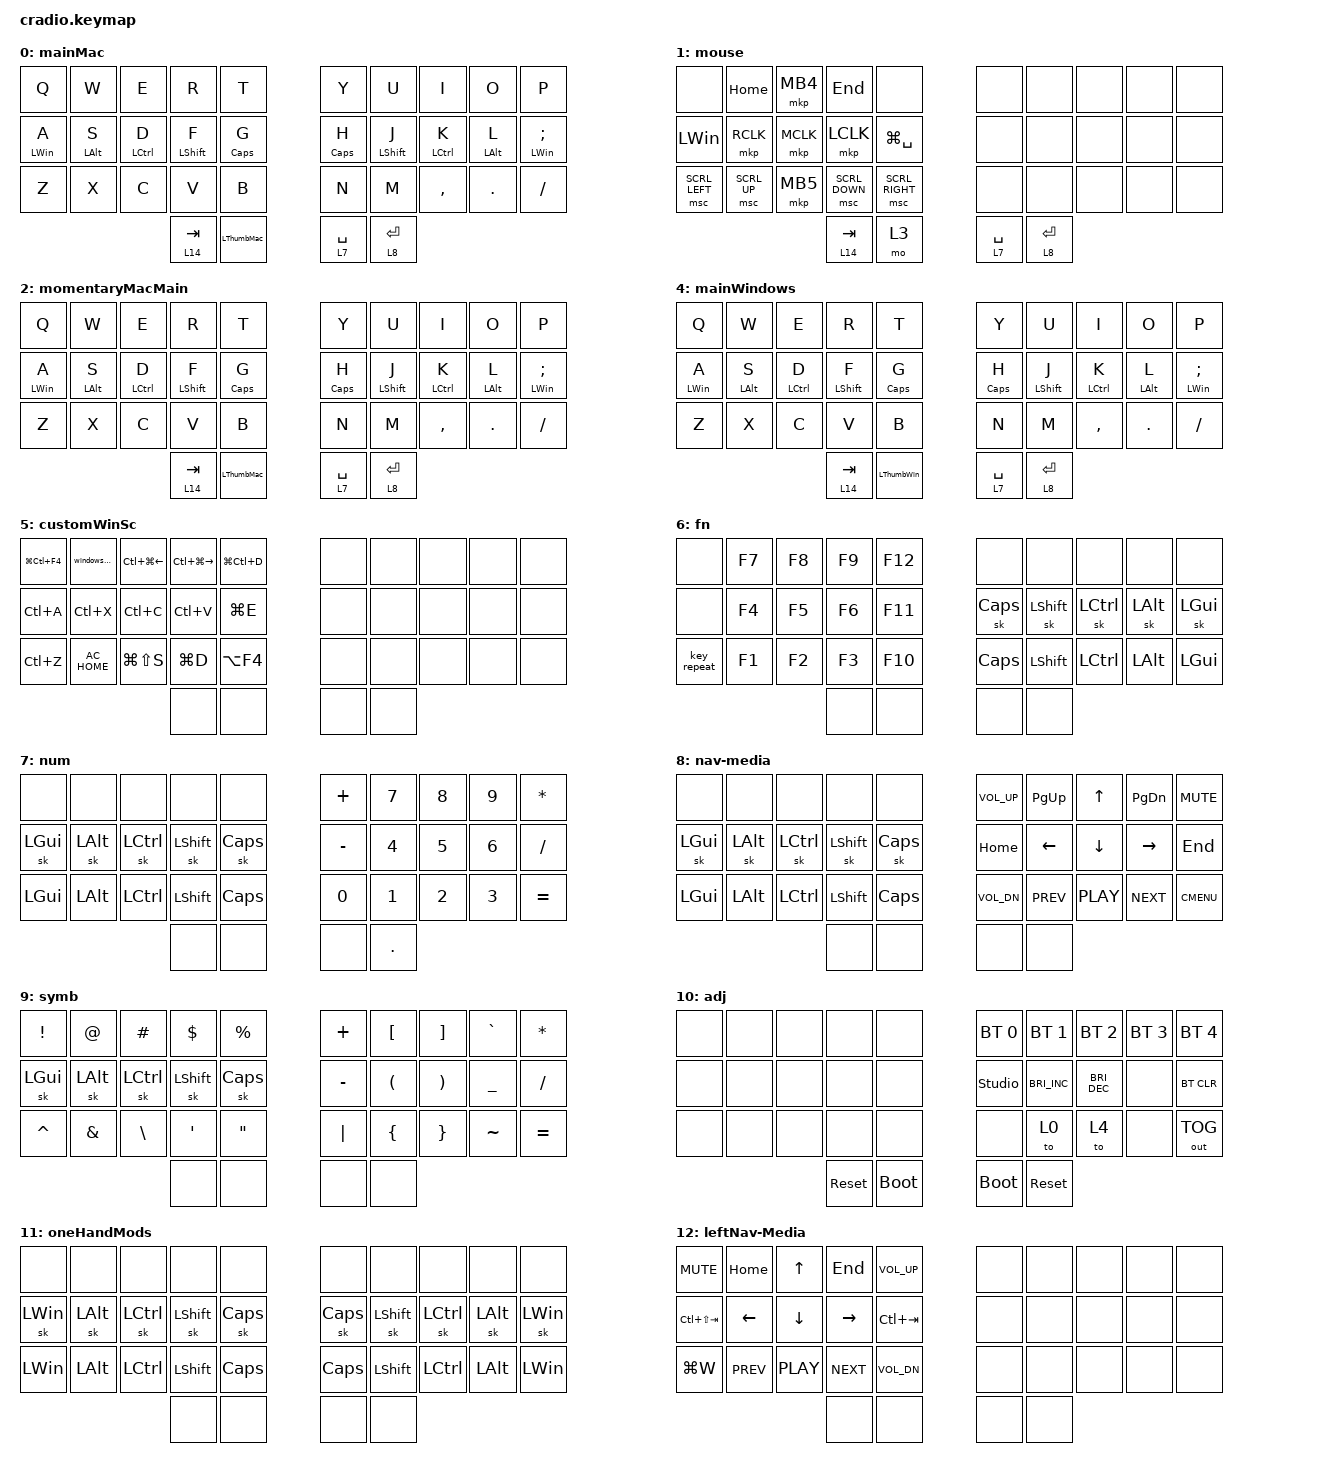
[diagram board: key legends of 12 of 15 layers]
#define ZMK_POINTING_DEFAULT_MOVE_VAL 1500  // default: 600
#define ZMK_POINTING_DEFAULT_SCRL_VAL 20    // default: 10

#include <behaviors.dtsi>
#include <dt-bindings/zmk/bt.h>
#include <dt-bindings/zmk/keys.h>
#include <dt-bindings/zmk/outputs.h>
#include <dt-bindings/zmk/pointing.h>

&sk {
    quick-release;
    lazy;
    release-after-ms = <800>;
};

&lt {
    flavor = "balanced";
    require-prior-idle-ms = <40>;
};

/ {
    behaviors {
        hmr: hmr {
            compatible = "zmk,behavior-hold-tap";
            #binding-cells = <2>;
            label = "hmr";
            bindings = <&kp>, <&kp>;

            tapping-term-ms = <280>;
            hold-trigger-on-release;             // delay positional check until key-release
            flavor = "balanced";
            require-prior-idle-ms = <200>;
            require-prior-idle-ms = <150>;
            quick-tap-ms = <175>;
            hold-trigger-key-positions = <0 1 2 3 4 10 11 12 13 14 20 21 22 23 24 30 31 32 33>;
        };

        hml: hml {
            compatible = "zmk,behavior-hold-tap";
            #binding-cells = <2>;
            label = "hml";
            bindings = <&kp>, <&kp>;

            tapping-term-ms = <280>;
            hold-trigger-on-release;
            flavor = "balanced";
            require-prior-idle-ms = <200>;
            quick-tap-ms = <175>;
            hold-trigger-key-positions = <5 6 7 8 9 15 16 17 18 19 25 26 27 28 29 32 33 30 31>;
        };

        tapSk_holdLayer: tapSk_holdLayer {
            compatible = "zmk,behavior-hold-tap";
            label = "TAPSK_HOLDLAYER";
            bindings = <&mo>, <&sk>;

            #binding-cells = <2>;
            tapping-term-ms = <80>;
            flavor = "tap-preferred";
            hold-while-undecided;
        };

        LThumbMac: LThumbMac {
            compatible = "zmk,behavior-tap-dance";
            label = "LTHUMBMAC";
            #binding-cells = <0>;
            bindings = <&tapSk_holdLayer 3 LEFT_SHIFT>, <&lt 5 LG(SPACE)>;

            tapping-term-ms = <380>;
        };

        tapToHoldMo: tapToHoldMo {
            compatible = "zmk,behavior-hold-tap";
            label = "TAPTOHOLDMO";
            #binding-cells = <2>;
            tapping-term-ms = <150>;
            flavor = "tap-preferred";
            hold-while-undecided;
            bindings = <&mo>, <&to>;
        };

        LThumbWin: LThumbWin {
            compatible = "zmk,behavior-tap-dance";
            label = "LTHUMBWIN";
            #binding-cells = <0>;
            bindings = <&tapSk_holdLayer 5 LEFT_SHIFT>, <&lt 0 LEFT_WIN>;

            tapping-term-ms = <380>;
        };
    };

    combos {
        compatible = "zmk,combos";

        capWords {
            bindings = <&caps_word>;
            key-positions = <13 16>;
            timeout-ms = <150>;
            require-prior-idle-ms = <100>;
        };

        toSymb {
            bindings = <&mo 9>;
            key-positions = <31 32>;
            timeout-ms = <150>;
            require-prior-idle-ms = <100>;
            slow-release;
        };

        escL {
            timeout-ms = <40>;
            bindings = <&kp ESCAPE>;
            key-positions = <3 2>;
            require-prior-idle-ms = <100>;
        };

        aphostrope {
            timeout-ms = <35>;
            bindings = <&kp SQT>;
            key-positions = <8 7>;
        };

        backR {
            bindings = <&kp BACKSPACE>;
            key-positions = <16 17>;
            timeout-ms = <40>;
            require-prior-idle-ms = <100>;
        };

        backL {
            bindings = <&kp BACKSPACE>;
            key-positions = <12 13>;
            timeout-ms = <40>;
            require-prior-idle-ms = <100>;
        };

        questionR {
            bindings = <&kp QUESTION>;
            key-positions = <27 28>;
            timeout-ms = <70>;
            require-prior-idle-ms = <40>;
        };

        wordDelLMac {
            bindings = <&kp LA(BACKSPACE)>;
            key-positions = <12 11>;
            timeout-ms = <40>;
            require-prior-idle-ms = <100>;
            layers = <0>;
        };

        wordDelRMac {
            bindings = <&kp LA(BACKSPACE)>;
            key-positions = <17 18>;
            timeout-ms = <40>;
            require-prior-idle-ms = <100>;
            layers = <0>;
        };

        delR {
            bindings = <&kp DELETE>;
            key-positions = <26 27>;
            timeout-ms = <40>;
            require-prior-idle-ms = <100>;
        };

        delL {
            bindings = <&kp DELETE>;
            key-positions = <22 23>;
            timeout-ms = <40>;
            require-prior-idle-ms = <100>;
        };

        LhandOHM {
            bindings = <&mo 11>;
            key-positions = <30 13>;
            timeout-ms = <40>;
            slow-release;
            require-prior-idle-ms = <100>;
        };

        RhandOHM {
            bindings = <&mo 11>;
            key-positions = <33 16>;
            timeout-ms = <40>;
            slow-release;
            require-prior-idle-ms = <100>;
        };

        toAdj {
            bindings = <&mo 10>;
            key-positions = <0 4>;
            timeout-ms = <150>;
            slow-release;
            require-prior-idle-ms = <100>;
        };

        toLeftMedia-Nav {
            bindings = <&mo 12>;
            key-positions = <31 1 2 3>;
            timeout-ms = <150>;
            slow-release;
            require-prior-idle-ms = <100>;
        };

        rightToLeft {
            bindings = <&sl 13>;
            key-positions = <12 11 13>;
            timeout-ms = <200>;
            slow-release;
            require-prior-idle-ms = <100>;
        };

        appWindows {
            bindings = <&kp LC(LA(DOWN))>;
            key-positions = <10 30>;
            timeout-ms = <40>;
            require-prior-idle-ms = <100>;
        };

        leftEnter {
            bindings = <&kp ENTER>;
            key-positions = <21 22>;
            timeout-ms = <40>;
            slow-release;
            require-prior-idle-ms = <80>;
        };

        wordDelRWin {
            bindings = <&kp LC(BACKSPACE)>;
            key-positions = <17 18>;
            timeout-ms = <40>;
            require-prior-idle-ms = <100>;
            layers = <4>;
        };

        wordDelLWin {
            bindings = <&kp LC(BACKSPACE)>;
            key-positions = <12 11>;
            timeout-ms = <40>;
            require-prior-idle-ms = <100>;
            layers = <4>;
        };

        toFn {
            bindings = <&mo 6>;
            key-positions = <11 12 13 31>;
            slow-release;
            timeout-ms = <40>;
            require-prior-idle-ms = <100>;
        };

        leftQuestion {
            bindings = <&kp QUESTION>;
            key-positions = <1 2>;
            timeout-ms = <70>;
            require-prior-idle-ms = <40>;
        };

        moMouse {
            bindings = <&mo 1>;
            key-positions = <31 13>;
            timeout-ms = <40>;
            slow-release;
            require-prior-idle-ms = <100>;
            layers = <0>;
        };

        openRecentlyClosed {
            bindings = <&kp LG(LS(T))>;
            key-positions = <1 0>;
            timeout-ms = <70>;
            require-prior-idle-ms = <40>;
        };

        newTab {
            bindings = <&kp LG(T)>;
            key-positions = <1 3>;
            timeout-ms = <70>;
            require-prior-idle-ms = <40>;
        };

        toMain {
            bindings = <&to 0>;
            key-positions = <13 20 31>;
            timeout-ms = <150>;
            slow-release;
            require-prior-idle-ms = <100>;
        };

        moMain {
            bindings = <&mo 2>;
            key-positions = <31 10 11 12 13>;
            timeout-ms = <150>;
            slow-release;
            require-prior-idle-ms = <100>;
        };

        toMouse {
            bindings = <&to 1>;
            key-positions = <31 10 13>;
            timeout-ms = <150>;
            slow-release;
            require-prior-idle-ms = <100>;
        };
    };

    macros {
        windowsMissionControl: new_macro {
            compatible = "zmk,behavior-macro";
            #binding-cells = <0>;
            bindings =
                <&macro_press>,
                <&kp LEFT_WIN>,
                <&macro_tap>,
                <&kp TAB>,
                <&macro_release>,
                <&kp LEFT_WIN>;

            label = "NEW_MACRO";
        };
    };

    keymap {
        compatible = "zmk,keymap";

        mainMac {
            bindings = <
&kp Q            &kp W            &kp E                &kp R              &kp T          &kp Y        &kp U              &kp I                &kp O            &kp P
&hml LEFT_WIN A  &hml LEFT_ALT S  &hml LEFT_CONTROL D  &hml LEFT_SHIFT F  &hml CAPS G    &hmr CAPS H  &hmr LEFT_SHIFT J  &hmr LEFT_CONTROL K  &hmr LEFT_ALT L  &hmr LEFT_WIN SEMICOLON
&kp Z            &kp X            &kp C                &kp V              &kp B          &kp N        &kp M              &kp COMMA            &kp DOT          &kp FSLH
                                                       &lt 14 TAB         &LThumbMac     &lt 7 SPACE  &lt 8 ENTER
            >;
        };

        mouse {
            bindings = <
&none           &kp HOME      &mkp MB4   &kp END         &none              &none        &none        &none  &none  &none
&kp LEFT_WIN    &mkp RCLK     &mkp MCLK  &mkp LCLK       &kp LG(SPACE)      &none        &none        &none  &none  &none
&msc SCRL_LEFT  &msc SCRL_UP  &mkp MB5   &msc SCRL_DOWN  &msc SCRL_RIGHT    &none        &none        &none  &none  &none
                                         &lt 14 TAB      &mo 3              &lt 7 SPACE  &lt 8 ENTER
            >;
        };

        momentaryMacMain {
            bindings = <
&kp Q            &kp W            &kp E                &kp R              &kp T          &kp Y        &kp U              &kp I                &kp O            &kp P
&hml LEFT_WIN A  &hml LEFT_ALT S  &hml LEFT_CONTROL D  &hml LEFT_SHIFT F  &hml CAPS G    &hmr CAPS H  &hmr LEFT_SHIFT J  &hmr LEFT_CONTROL K  &hmr LEFT_ALT L  &hmr LEFT_WIN SEMICOLON
&kp Z            &kp X            &kp C                &kp V              &kp B          &kp N        &kp M              &kp COMMA            &kp DOT          &kp FSLH
                                                       &lt 14 TAB         &LThumbMac     &lt 7 SPACE  &lt 8 ENTER
            >;
        };

        macShorcuts0 {
            bindings = <
&kp LS(LA(LC(LG(LEFT))))  &kp LG(LS(LC(LA(RIGHT))))  &kp LC(LG(LA(A)))         &kp LC(LG(LA(B)))     &kp LG(LC(D))    &none  &none  &none  &none  &none
&kp LG(A)                 &kp LG(X)                  &kp LG(C)                 &kp LG(V)             &kp LG(LC(F))    &none  &none  &none  &none  &none
&kp LG(Z)                 &kp LG(LS(N5))             &kp LG(LS(LC(NUMBER_4)))  &kp LG(D)             &kp LG(W)        &none  &none  &none  &none  &none
                                                                               &kp LG(LEFT_BRACKET)  &none            &none  &none
            >;
        };

        mainWindows {
            bindings = <
&kp Q            &kp W            &kp E                &kp R              &kp T          &kp Y        &kp U              &kp I                &kp O            &kp P
&hml LEFT_WIN A  &hml LEFT_ALT S  &hml LEFT_CONTROL D  &hml LEFT_SHIFT F  &hml CAPS G    &hmr CAPS H  &hmr LEFT_SHIFT J  &hmr LEFT_CONTROL K  &hmr LEFT_ALT L  &hmr LEFT_WIN SEMICOLON
&kp Z            &kp X            &kp C                &kp V              &kp B          &kp N        &kp M              &kp COMMA            &kp DOT          &kp FSLH
                                                       &lt 14 TAB         &LThumbWin     &lt 7 SPACE  &lt 8 ENTER
            >;
        };

        customWinSc {
            bindings = <
&kp LG(LC(F4))  &windowsMissionControl  &kp LC(LG(LEFT))  &kp LC(LG(RIGHT))  &kp LG(LC(D))    &none  &none  &none  &none  &none
&kp LC(A)       &kp LC(X)               &kp LC(C)         &kp LC(V)          &kp LG(E)        &none  &none  &none  &none  &none
&kp LC(Z)       &kp C_AC_HOME           &kp LG(LS(S))     &kp LG(D)          &kp LA(F4)       &none  &none  &none  &none  &none
                                                          &none              &none            &none  &none
            >;
        };

        fn {
            bindings = <
&none        &kp F7  &kp F8  &kp F9  &kp F12    &none     &none           &none      &none     &none
&none        &kp F4  &kp F5  &kp F6  &kp F11    &sk CAPS  &sk LEFT_SHIFT  &sk LCTRL  &sk LALT  &sk LEFT_GUI
&key_repeat  &kp F1  &kp F2  &kp F3  &kp F10    &kp CAPS  &kp LEFT_SHIFT  &kp LCTRL  &kp LALT  &kp LEFT_GUI
                             &none   &none      &none     &none
            >;
        };

        num {
            bindings = <
&none         &none     &none      &none           &none       &kp PLUS   &kp N7   &kp N8  &kp N9  &kp ASTERISK
&sk LEFT_GUI  &sk LALT  &sk LCTRL  &sk LSHFT       &sk CAPS    &kp MINUS  &kp N4   &kp N5  &kp N6  &kp SLASH
&kp LEFT_GUI  &kp LALT  &kp LCTRL  &kp LEFT_SHIFT  &kp CAPS    &kp N0     &kp N1   &kp N2  &kp N3  &kp EQUAL
                                   &none           &none       &none      &kp DOT
            >;
        };

        nav-media {
            bindings = <
&none         &none     &none      &none           &none       &kp C_VOL_UP  &kp PG_UP   &kp UP      &kp PG_DN   &kp C_MUTE
&sk LEFT_GUI  &sk LALT  &sk LCTRL  &sk LSHFT       &sk CAPS    &kp HOME      &kp LEFT    &kp DOWN    &kp RIGHT   &kp END
&kp LEFT_GUI  &kp LALT  &kp LCTRL  &kp LEFT_SHIFT  &kp CAPS    &kp C_VOL_DN  &kp C_PREV  &kp C_PLAY  &kp C_NEXT  &kp K_CMENU
                                   &none           &none       &none         &none
            >;
        };

        symb {
            bindings = <
&kp EXCL      &kp AT    &kp HASH       &kp DLLR          &kp PERCENT          &kp PLUS   &kp LEFT_BRACKET      &kp RIGHT_BRACKET      &kp GRAVE  &kp STAR
&sk LEFT_GUI  &sk LALT  &sk LCTRL      &sk LEFT_SHIFT    &sk CAPS             &kp MINUS  &kp LEFT_PARENTHESIS  &kp RIGHT_PARENTHESIS  &kp UNDER  &kp SLASH
&kp CARET     &kp AMPS  &kp BACKSLASH  &kp SINGLE_QUOTE  &kp DOUBLE_QUOTES    &kp PIPE   &kp LEFT_BRACE        &kp RIGHT_BRACE        &kp TILDE  &kp EQUAL
                                       &none             &none                &none      &none
            >;
        };

        adj {
            bindings = <
&none  &none  &none  &none       &none          &bt BT_SEL 0    &bt BT_SEL 1   &bt BT_SEL 2          &bt BT_SEL 3  &bt BT_SEL 4
&none  &none  &none  &none       &none          &studio_unlock  &kp C_BRI_INC  &kp C_BRIGHTNESS_DEC  &none         &bt BT_CLR
&none  &none  &none  &none       &none          &none           &to 0          &to 4                 &none         &out OUT_TOG
                     &sys_reset  &bootloader    &bootloader     &sys_reset
            >;
        };

        oneHandMods {
            bindings = <
&none         &none     &none      &none      &none       &none     &none      &none      &none     &none
&sk LEFT_WIN  &sk LALT  &sk LCTRL  &sk LSHFT  &sk CAPS    &sk CAPS  &sk LSHFT  &sk LCTRL  &sk LALT  &sk LEFT_WIN
&kp LEFT_WIN  &kp LALT  &kp LCTRL  &kp LSHFT  &kp CAPS    &kp CAPS  &kp LSHFT  &kp LCTRL  &kp LALT  &kp LEFT_WIN
                                   &none      &none       &none     &none
            >;
        };

        leftNav-Media {
            bindings = <
&kp C_MUTE       &kp HOME    &kp UP      &kp END     &kp C_VOLUME_UP    &none  &none  &none  &none  &none
&kp LC(LS(TAB))  &kp LEFT    &kp DOWN    &kp RIGHT   &kp LC(TAB)        &none  &none  &none  &none  &none
&kp LG(W)        &kp C_PREV  &kp C_PLAY  &kp C_NEXT  &kp C_VOL_DN       &none  &none  &none  &none  &none
                                         &none       &none              &none  &none
            >;
        };

        rightToLeftLayer {
            bindings = <
&kp P     &kp O    &kp I      &kp U    &kp Y        &none  &none  &none  &none  &none
&kp SEMI  &kp L    &kp K      &kp J    &kp H        &none  &none  &none  &none  &none
&kp FSLH  &kp DOT  &kp COMMA  &kp M    &kp N        &none  &none  &none  &none  &none
                              &kp RET  &kp SPACE    &none  &none
            >;
        };

        super+KP {
            bindings = <
&kp LC(LG(LA(LS(Q))))  &kp LC(LG(LA(LS(W))))  &kp LC(LG(LA(LS(E))))  &kp LC(LG(LA(LS(R))))  &kp LC(LG(LA(LS(T))))    &kp LC(LG(LA(LS(Y))))  &kp LC(LG(LA(LS(U))))  &kp LC(LG(LA(LS(I))))  &kp LC(LG(LA(LS(O))))       &kp LC(LG(LA(LS(P))))
&kp LC(LG(LA(LS(A))))  &kp LC(LG(LA(LS(S))))  &kp LC(LG(LA(LS(D))))  &kp LC(LG(LA(LS(F))))  &kp LC(LG(LA(LS(G))))    &kp LC(LG(LA(LS(H))))  &kp LC(LG(LA(LS(J))))  &kp LC(LG(LA(LS(K))))  &kp LC(LG(LA(LS(L))))       &kp LC(LG(LA(LS(SEMICOLON))))
&kp LC(LG(LA(LS(Z))))  &kp LC(LG(LA(LS(X))))  &kp LC(LG(LA(LS(C))))  &kp LC(LG(LA(LS(V))))  &kp LC(LG(LA(LS(B))))    &kp LC(LG(LA(LS(N))))  &kp LC(LG(LA(LS(M))))  &kp LC(COMMA)          &kp LC(LG(LA(LS(PERIOD))))  &kp LC(LG(LA(LS(SLASH))))
                                                                     &none                  &none                    &none                  &none
            >;
        };
    };
};
